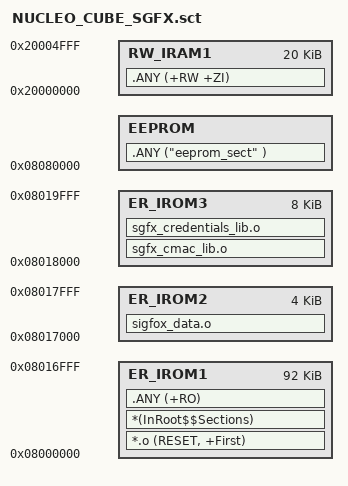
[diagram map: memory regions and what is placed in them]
; *************************************************************
; *** Scatter-Loading Description File generated by uVision ***
; *************************************************************

LR_IROM1 0x08000000 0x00017000  {    ; load region size_region
  ER_IROM1 0x08000000 0x00017000  {  ; load address = execution address
   *.o (RESET, +First)
   *(InRoot$$Sections)
   .ANY (+RO)
  }

  RW_IRAM1 0x20000000 0x00005000  {  ; RW data
   .ANY (+RW +ZI)
  }
}

LR_IROM2 0x08017000 0x00001000  {    ; load region size_region
  ER_IROM2 0x08017000   0x00001000  { ; sigfox_data Area
  sigfox_data.o
  }
}

LR_IROM3 0x08018000   0x00002000   {    ; load region size_region
  ER_IROM3 0x08018000   0x00002000  { ; cmac_code Area
   sgfx_cmac_lib.o
   sgfx_credentials_lib.o
  }
}

EEPROM 0x08080000
{
 EEPROM 0x08080000
 {
   .ANY ("eeprom_sect" )
 }
}


